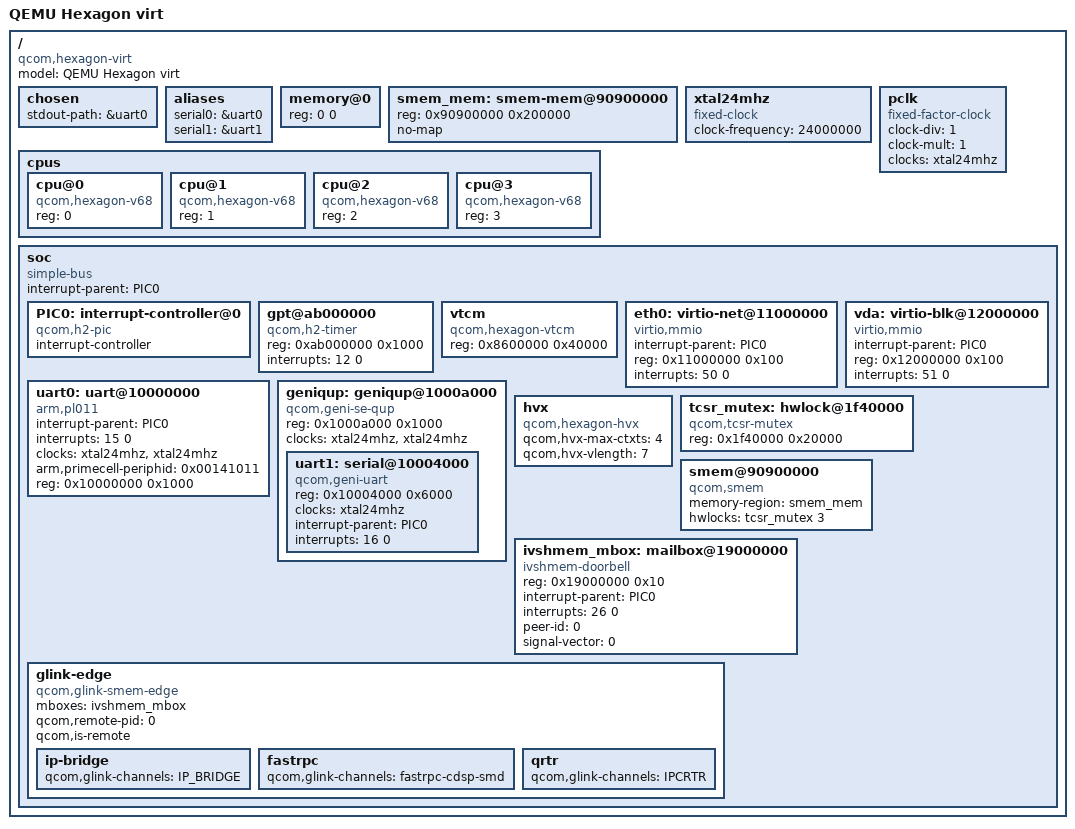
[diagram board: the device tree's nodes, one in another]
// SPDX-License-Identifier: GPL-2.0-only
/dts-v1/;

/ {
	#address-cells = <1>;
	#size-cells = <1>;
	model = "QEMU Hexagon virt";
	compatible = "qcom,hexagon-virt";

	chosen {
		stdout-path = &uart0;
	};

	aliases {
		serial0 = &uart0;
		serial1 = &uart1;
	};

	memory@0 { device_type = "memory"; reg = <0 0>; };

	smem_mem: smem-mem@90900000 {
		reg = <0x90900000 0x200000>;
		no-map;
	};

	cpus {
		#address-cells = <1>;
		#size-cells = <0>;

		cpu@0 {
			device_type = "cpu";
			compatible = "qcom,hexagon-v68";
			reg = <0>;
		};

		cpu@1 {
			device_type = "cpu";
			compatible = "qcom,hexagon-v68";
			reg = <1>;
		};

		cpu@2 {
			device_type = "cpu";
			compatible = "qcom,hexagon-v68";
			reg = <2>;
		};

		cpu@3 {
			device_type = "cpu";
			compatible = "qcom,hexagon-v68";
			reg = <3>;
		};
	};

	xtal24mhz: xtal24mhz {
		#clock-cells = <0>;
		compatible = "fixed-clock";
		clock-frequency = <24000000>;
	};

	pclk: pclk {
		#clock-cells = <0>;
		compatible = "fixed-factor-clock";
		clock-div = <1>;
		clock-mult = <1>;
		clocks = <&xtal24mhz>;
	};

	soc: soc {
		compatible = "simple-bus";
		#address-cells = <1>;
		#size-cells = <1>;
		ranges;
		interrupt-parent = <&PIC0>;

		PIC0: interrupt-controller@0 {
			compatible = "qcom,h2-pic";
			interrupt-controller;
			#interrupt-cells = <2>;
		};

		gpt@ab000000 {
			compatible = "qcom,h2-timer";
			reg = <0xab000000 0x1000>;
			interrupts = <12 0>;
		};

		vtcm {
			compatible = "qcom,hexagon-vtcm";
			reg = <0x8600000 0x40000>;
		};

		eth0: virtio-net@11000000 {
			compatible = "virtio,mmio";
			interrupt-parent = <&PIC0>;
			reg = <0x11000000 0x100>;
			interrupts = <50 0>;
		};

		vda: virtio-blk@12000000 {
			compatible = "virtio,mmio";
			interrupt-parent = <&PIC0>;
			reg = <0x12000000 0x100>;
			interrupts = <51 0>;
		};

		uart0: uart@10000000 {
			compatible = "arm,pl011", "arm,primecell";
			interrupt-parent = <&PIC0>;
			interrupts = <15 0>;
			clocks = <&xtal24mhz>, <&xtal24mhz>;
			clock-names = "uartclk", "apb_pclk";
			arm,primecell-periphid = <0x00141011>;
			reg = <0x10000000 0x1000>;
		};

		geniqup: geniqup@1000a000 {
			compatible = "qcom,geni-se-qup";
			reg = <0x1000a000 0x1000>;
			clocks = <&xtal24mhz>, <&xtal24mhz>;
			clock-names = "m-ahb", "s-ahb";
			#address-cells = <1>;
			#size-cells = <1>;
			ranges;

			uart1: serial@10004000 {
				compatible = "qcom,geni-uart";
				reg = <0x10004000 0x6000>;
				clocks = <&xtal24mhz>;
				clock-names = "se";
				interrupt-parent = <&PIC0>;
				interrupts = <16 0>;
			};
		};

		hvx {
			compatible = "qcom,hexagon-hvx";
			qcom,hvx-max-ctxts = <4>;
			qcom,hvx-vlength = <7>;
		};

		tcsr_mutex: hwlock@1f40000 {
			compatible = "qcom,tcsr-mutex";
			reg = <0x1f40000 0x20000>;
			#hwlock-cells = <1>;
		};

		smem@90900000 {
			compatible = "qcom,smem";
			memory-region = <&smem_mem>;
			hwlocks = <&tcsr_mutex 3>;
		};

		ivshmem_mbox: mailbox@19000000 {
			compatible = "ivshmem-doorbell";
			reg = <0x19000000 0x10>;
			interrupt-parent = <&PIC0>;
			interrupts = <26 0>;
			peer-id = <0>;
			signal-vector = <0>;
			#mbox-cells = <0>;
		};

		glink-edge {
			compatible = "qcom,glink-smem-edge";
			mboxes = <&ivshmem_mbox>;
			qcom,remote-pid = <0>;
			qcom,is-remote;

			ip-bridge {
				qcom,glink-channels = "IP_BRIDGE";
			};

			fastrpc {
				qcom,glink-channels = "fastrpc-cdsp-smd";
			};

			qrtr {
				qcom,glink-channels = "IPCRTR";
			};
		};
	};
};
